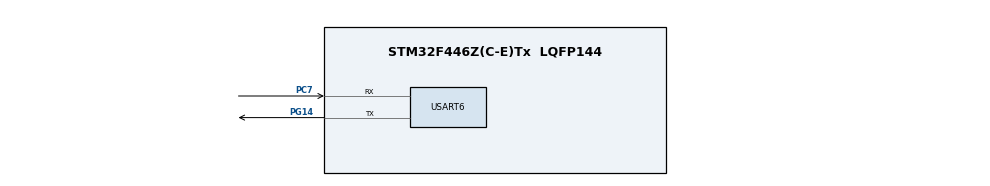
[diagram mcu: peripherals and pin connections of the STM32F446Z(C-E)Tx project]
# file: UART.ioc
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Mcu.Family=STM32F4
Mcu.Name=STM32F446Z(C-E)Tx
Mcu.Package=LQFP144
NVIC.PriorityGroup=NVIC_PRIORITYGROUP_4
PC7.Mode=Asynchronous
PC7.Signal=USART6_RX
PG14.Mode=Asynchronous
PG14.Signal=USART6_TX
ProjectManager.HeapSize=0x200
ProjectManager.StackSize=0x400
ProjectManager.TargetToolchain=EWARM V8.50
RCC.APB2CLKDivider=RCC_HCLK_DIV2
RCC.APB2Freq_Value=8000000
RCC.APB2TimFreq_Value=16000000
RCC.CortexFreq_Value=16000000
RCC.USBFreq_Value=96000000
RCC.VCOOutputFreq_Value=192000000
USART6.VirtualMode=VM_ASYNC
board=custom

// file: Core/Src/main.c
/* USER CODE BEGIN Header */
/**
  ******************************************************************************
  * @file           : main.c
  * @brief          : Main program body
  ******************************************************************************
  * @attention
  *
  * Copyright (c) 2026 STMicroelectronics.
  * All rights reserved.
  *
  * This software is licensed under terms that can be found in the LICENSE file
  * in the root directory of this software component.
  * If no LICENSE file comes with this software, it is provided AS-IS.
  *
  ******************************************************************************
  */
#include "main.h"
#include <stdint.h>
/* USER CODE END Header */

UART_HandleTypeDef huart6;

void SystemClock_Config(void);
static void MX_GPIO_Init(void);

/* USER CODE BEGIN 0 */
#define AHB1_BASE 0x40020000
#define APB2_BASE 0x40010000

#define RCC_BASE (AHB1_BASE + 0x3800)

#define GPIOG_BASE (AHB1_BASE + 0x1800)
#define USART6_BASE (APB2_BASE + 0x1400)

#define RCC_AHB1ENR (*(volatile uint32_t*)(RCC_BASE + 0x30))
#define RCC_APB2ENR (*(volatile uint32_t*)(RCC_BASE + 0x44))

#define GIPOG_MODER (*(volatile uint32_t*)GPIOG_BASE)
#define GPIOG_AFRH (*(volatile uint32_t*)(GPIOG_BASE + 0x24))

#define USART6_SR (*(volatile uint32_t*)USART6_BASE)
#define USART6_DR (*(volatile uint32_t*)(USART6_BASE + 0x04))
#define USART6_BRR (*(volatile uint32_t*)(USART6_BASE + 0x08))
#define USART6_CR1 (*(volatile uint32_t*)(USART6_BASE + 0x0C))

/* USER CODE END 0 */

int main(void)
{

  /* MCU Configuration--------------------------------------------------------*/

  /* Reset of all peripherals, Initializes the Flash interface and the Systick. */
  HAL_Init();

  /* Configure the system clock */
  SystemClock_Config();

  /* Initialize all configured peripherals */
  MX_GPIO_Init();
  MX_USART6_UART_Init();
  /* USER CODE BEGIN 2 */

  /* 1. Enable Clock */
  RCC_AHB1ENR |= (1u << 6); // GPIOGEN
  RCC_APB2ENR |= (1u << 5);   // USART6EN

  /* 2. Alternate Function Mode */
  GIPOG_MODER &= ~(((1u << 2) - 1) << (2 * 14)); // P14 -> Alternate Function mode
  GIPOG_MODER |= (1u << 1) << (2 * 14);

  GPIOG_AFRH &= ~(((1u << 4) - 1) << (4 * 6));
  GPIOG_AFRH |= (1u << 3) << (4 * 6); // ARRH14 -> 1000 (AF8)

  /* 3. Calc BR - NOTE: BRR calc. first, USART starts transmission once TE is set */
  USART6_BRR = (16000000u + 9600u / 2) / 9600u;

  /* 4. Set UE, TE */
  USART6_CR1 |= (1u << 3) | (1u << 13); // set UE, TE

  char *data = "DUMMYdummy";
  uint8_t data_size = 10;
  uint8_t idx = 0; // NOTE: volatile not required since it is not a register (No cache in compiler opti.)

  /* USER CODE END 2 */

  /* Infinite loop */
  /* USER CODE BEGIN WHILE */
  while (idx < data_size)
  {
    /* USER CODE END WHILE */

    /* USER CODE BEGIN 3 */

    /* 5. Transmit */
    // TXE check -> if empty: transmit data -> check TC -> if TC: repeat
    if ((USART6_SR >> 7) & 1u) { // if TXE, write data to DR
      USART6_DR = data[idx++];
    }
    // while (!((USART6_SR >> 6) & 1u)) {} // Wait until TC becomes 1, TODO: Check if it is emittable regarding TDR -> Shift -> TX archi.
  }
  /* USER CODE END 3 */
}

void SystemClock_Config(void)
{
  RCC_OscInitTypeDef RCC_OscInitStruct = {0};
  RCC_ClkInitTypeDef RCC_ClkInitStruct = {0};

  /** Configure the main internal regulator output voltage
  */
  __HAL_RCC_PWR_CLK_ENABLE();
  __HAL_PWR_VOLTAGESCALING_CONFIG(PWR_REGULATOR_VOLTAGE_SCALE3);

  /** Initializes the RCC Oscillators according to the specified parameters
  * in the RCC_OscInitTypeDef structure.
  */
  RCC_OscInitStruct.OscillatorType = RCC_OSCILLATORTYPE_HSI;
  RCC_OscInitStruct.HSIState = RCC_HSI_ON;
  RCC_OscInitStruct.HSICalibrationValue = RCC_HSICALIBRATION_DEFAULT;
  RCC_OscInitStruct.PLL.PLLState = RCC_PLL_NONE;
  if (HAL_RCC_OscConfig(&RCC_OscInitStruct) != HAL_OK)
  {
    Error_Handler();
  }

  /** Initializes the CPU, AHB and APB buses clocks
  */
  RCC_ClkInitStruct.ClockType = RCC_CLOCKTYPE_HCLK|RCC_CLOCKTYPE_SYSCLK
                              |RCC_CLOCKTYPE_PCLK1|RCC_CLOCKTYPE_PCLK2;
  RCC_ClkInitStruct.SYSCLKSource = RCC_SYSCLKSOURCE_HSI;
  RCC_ClkInitStruct.AHBCLKDivider = RCC_SYSCLK_DIV1;
  RCC_ClkInitStruct.APB1CLKDivider = RCC_HCLK_DIV1;
  RCC_ClkInitStruct.APB2CLKDivider = RCC_HCLK_DIV2;

  if (HAL_RCC_ClockConfig(&RCC_ClkInitStruct, FLASH_LATENCY_0) != HAL_OK)
  {
    Error_Handler();
  }
}

static void MX_USART6_UART_Init(void)
{

  huart6.Instance = USART6;
  huart6.Init.BaudRate = 115200;
  huart6.Init.WordLength = UART_WORDLENGTH_8B;
  huart6.Init.StopBits = UART_STOPBITS_1;
  huart6.Init.Parity = UART_PARITY_NONE;
  huart6.Init.Mode = UART_MODE_TX_RX;
  huart6.Init.HwFlowCtl = UART_HWCONTROL_NONE;
  huart6.Init.OverSampling = UART_OVERSAMPLING_16;
  if (HAL_UART_Init(&huart6) != HAL_OK)
  {
    Error_Handler();
  }

}

static void MX_GPIO_Init(void)
{

  /* GPIO Ports Clock Enable */
  __HAL_RCC_GPIOC_CLK_ENABLE();
  __HAL_RCC_GPIOG_CLK_ENABLE();

}

void Error_Handler(void)
{
  __disable_irq();
  while (1)
  {
  }
}
